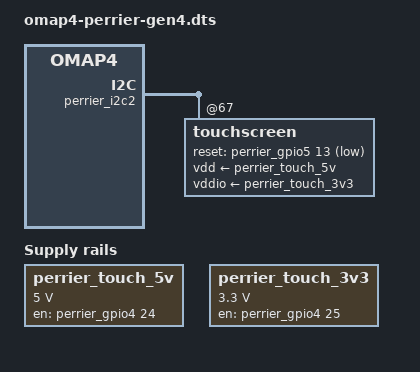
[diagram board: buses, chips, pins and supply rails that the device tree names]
// SPDX-License-Identifier: GPL-2.0-only
// Stock perrier_init, idefix_touch_init and live stock pinmux readback.
#include "../perrier-cold-ethernet/omap4-perrier-cold-ethernet.dts"

&perrier_core_pins {
    perrier_touch_5v_pin: touch-5v-pin {
        pinctrl-single,pins = <OMAP4_IOPAD(0x112, 0x0003)>;
    };
    perrier_touch_3v3_pin: touch-3v3-pin {
        pinctrl-single,pins = <OMAP4_IOPAD(0x114, 0x0003)>;
    };
    perrier_touch_pins: touch-pins {
        pinctrl-single,pins = <
            OMAP4_IOPAD(0x140, 0x0003) // GPIO141 reset output
            OMAP4_IOPAD(0x142, 0x731b) // GPIO142 IRQ input/pull-up/off wake
        >;
    };
    perrier_touch_i2c_pins: touch-i2c-pins {
        pinctrl-single,pins = <
            OMAP4_IOPAD(0x126, 0x0100)
            OMAP4_IOPAD(0x128, 0x0100)
        >;
    };
};

&{/} {
    perrier_touch_5v: regulator-touch-5v {
        compatible = "regulator-fixed";
        regulator-name = "perrier-touch-5v";
        regulator-min-microvolt = <5000000>;
        regulator-max-microvolt = <5000000>;
        pinctrl-names = "default";
        pinctrl-0 = <&perrier_touch_5v_pin>;
        gpio = <&perrier_gpio4 24 GPIO_ACTIVE_HIGH>; // stock tp_5v_en GPIO120
        enable-active-high;
    };
    perrier_touch_3v3: regulator-touch-3v3 {
        compatible = "regulator-fixed";
        regulator-name = "perrier-touch-3v3";
        regulator-min-microvolt = <3300000>;
        regulator-max-microvolt = <3300000>;
        pinctrl-names = "default";
        pinctrl-0 = <&perrier_touch_3v3_pin>;
        gpio = <&perrier_gpio4 25 GPIO_ACTIVE_HIGH>; // stock tp_3v3_en GPIO121
        enable-active-high;
    };
};

&perrier_i2c2 {
    pinctrl-names = "default";
    pinctrl-0 = <&perrier_touch_i2c_pins>;
    touchscreen@67 {
        pinctrl-names = "default";
        pinctrl-0 = <&perrier_touch_pins>;
        reset-gpios = <&perrier_gpio5 13 GPIO_ACTIVE_LOW>;
        vdd-supply = <&perrier_touch_5v>;
        vddio-supply = <&perrier_touch_3v3>;
    };
};
